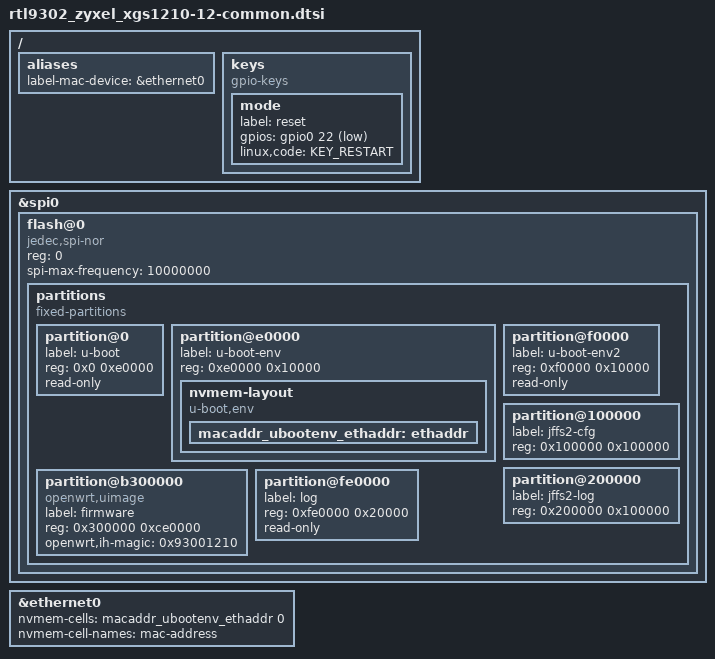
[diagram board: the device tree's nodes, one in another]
// SPDX-License-Identifier: GPL-2.0-or-later
/dts-v1/;

#include "rtl9302_zyxel_xgs1x10-12-common.dtsi"

/ {
	aliases {
		label-mac-device = &ethernet0;
	};

	keys {
		compatible = "gpio-keys";

		mode {
			label = "reset";
			gpios = <&gpio0 22 GPIO_ACTIVE_LOW>;
			linux,code = <KEY_RESTART>;
		};
	};
};

&spi0 {
	status = "okay";
	flash@0 {
		compatible = "jedec,spi-nor";
		reg = <0>;
		spi-max-frequency = <10000000>;

		partitions {
			compatible = "fixed-partitions";
			#address-cells = <1>;
			#size-cells = <1>;

			partition@0 {
				label = "u-boot";
				reg = <0x0 0xe0000>;
				read-only;
			};
			partition@e0000 {
				label = "u-boot-env";
				reg = <0xe0000 0x10000>;

				nvmem-layout {
					compatible = "u-boot,env";

					macaddr_ubootenv_ethaddr: ethaddr {
						#nvmem-cell-cells = <1>;
					};
				};
			};
			partition@f0000 {
				label = "u-boot-env2";
				reg = <0xf0000 0x10000>;
				read-only;
			};
			partition@100000 {
				label = "jffs2-cfg";
				reg = <0x100000 0x100000>;
			};
			partition@200000 {
				label = "jffs2-log";
				reg = <0x200000 0x100000>;
			};
			partition@b300000 {
				label = "firmware";
				reg = <0x300000 0xce0000>;
				compatible = "openwrt,uimage", "denx,uimage";
				openwrt,ih-magic = <0x93001210>;
			};
			partition@fe0000 {
				label = "log";
				reg = <0xfe0000 0x20000>;
				read-only;
			};
		};
	};
};

&ethernet0 {
	nvmem-cells = <&macaddr_ubootenv_ethaddr 0>;
	nvmem-cell-names = "mac-address";
};
